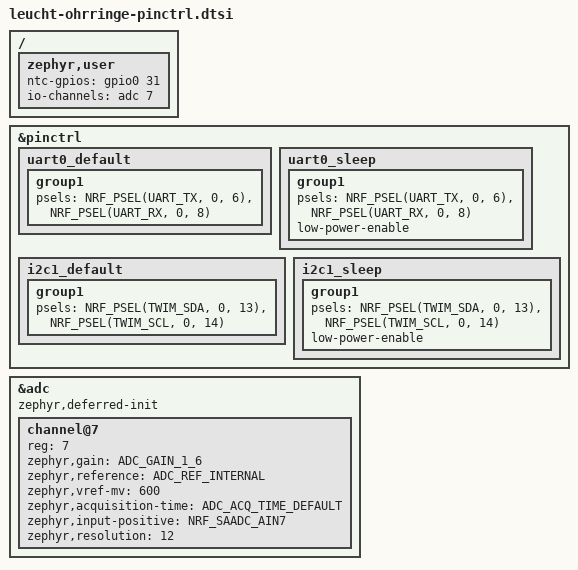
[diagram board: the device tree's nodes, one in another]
#include <zephyr/dt-bindings/pinctrl/nrf-pinctrl.h>
#include <zephyr/dt-bindings/adc/nrf-saadc.h>

&pinctrl {
	/*
	 * CH340N USB-to-UART bridge.
	 *
	 * nRF P0.06 TX -> CH340N RX
	 * nRF P0.08 RX <- CH340N TX
	 */
	uart0_default: uart0_default {
		group1 {
			psels = <NRF_PSEL(UART_TX, 0, 6)>,
				<NRF_PSEL(UART_RX, 0, 8)>;
		};
	};

	uart0_sleep: uart0_sleep {
		group1 {
			psels = <NRF_PSEL(UART_TX, 0, 6)>,
				<NRF_PSEL(UART_RX, 0, 8)>;

			low-power-enable;
		};
	};

	/*
	 * ICM-42670-L:
	 *
	 * SDA = P0.13
	 * SCL = P0.14
	 */
	i2c1_default: i2c1_default {
		group1 {
			psels = <NRF_PSEL(TWIM_SDA, 0, 13)>,
				<NRF_PSEL(TWIM_SCL, 0, 14)>;
		};
	};

	i2c1_sleep: i2c1_sleep {
		group1 {
			psels = <NRF_PSEL(TWIM_SDA, 0, 13)>,
				<NRF_PSEL(TWIM_SCL, 0, 14)>;

			low-power-enable;
		};
	};
};

&adc {
	#address-cells = <1>;
	#size-cells = <0>;
	status = "okay";
	zephyr,deferred-init;

	channel@7 {
		reg = <7>;
		zephyr,gain = "ADC_GAIN_1_6";
		zephyr,reference = "ADC_REF_INTERNAL";
		zephyr,vref-mv = <600>;
		zephyr,acquisition-time = <ADC_ACQ_TIME_DEFAULT>;
		zephyr,input-positive = <NRF_SAADC_AIN7>; /* P0.31 */
		zephyr,resolution = <12>;
	};
};

/ {
	zephyr,user {
		ntc-gpios = <&gpio0 31 0>;
		io-channels = <&adc 7>;
	};
};
